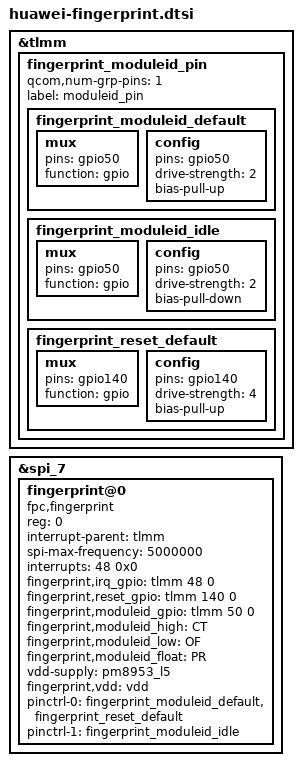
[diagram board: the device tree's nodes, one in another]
&tlmm {
	fingerprint_moduleid_pin {
		qcom,num-grp-pins = <1>;
		label = "moduleid_pin";
		fingerprint_moduleid_default: fingerprint_moduleid_default {
			mux {
				pins = "gpio50";
				function = "gpio";
			};
			config {
				pins = "gpio50";
				drive-strength = <2>;
				bias-pull-up;
			};
		};
		fingerprint_moduleid_idle: fingerprint_moduleid_idle {
			mux {
				pins = "gpio50";
				function = "gpio";
			};
			config {
				pins = "gpio50";
				drive-strength = <2>;
				bias-pull-down;
			};
		};
		fingerprint_reset_default: fingerprint_reset_default {
			mux {
				pins = "gpio140";
				function = "gpio";
			};
			config {
				pins = "gpio140";
				drive-strength = <4>;
				bias-pull-up;
			};
		};
	};
};

&spi_7 {
	status = "ok";
	fingerprint@0 {
		compatible = "fpc,fingerprint";
		reg = <0>;
		interrupt-parent = <&tlmm>;
		spi-max-frequency = <5000000>;
		interrupts = <48 0x0>;
		fingerprint,irq_gpio = <&tlmm 48 0>;
		fingerprint,reset_gpio = <&tlmm 140 0>;
		fingerprint,moduleid_gpio = <&tlmm 50 0>;
		fingerprint,moduleid_high = "CT";
		fingerprint,moduleid_low = "OF";
		fingerprint,moduleid_float = "PR";
		vdd-supply = <&pm8953_l5>;
		fingerprint,vdd = "vdd";
		pinctrl-names = "default", "idle";
		pinctrl-0 = <&fingerprint_moduleid_default &fingerprint_reset_default>;
		pinctrl-1 = <&fingerprint_moduleid_idle>;
		status = "ok";
	};
};
